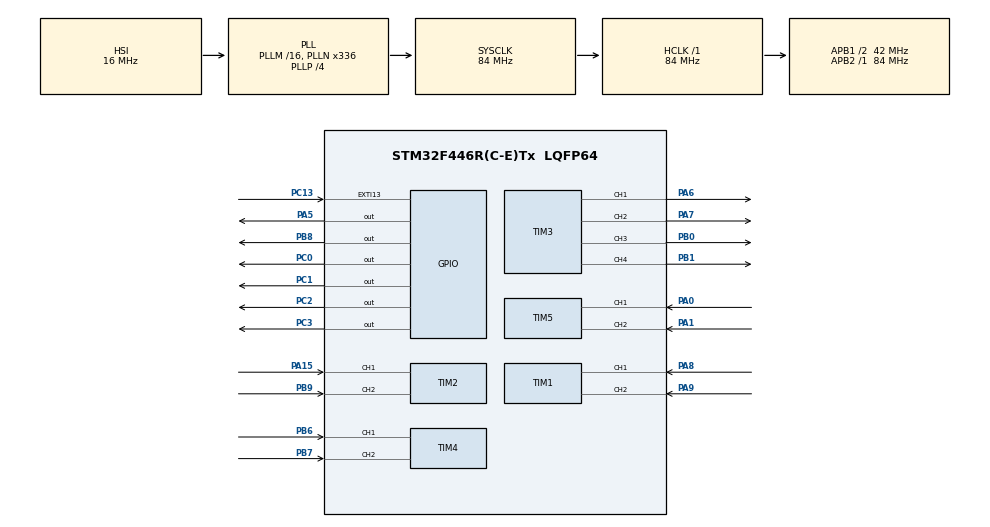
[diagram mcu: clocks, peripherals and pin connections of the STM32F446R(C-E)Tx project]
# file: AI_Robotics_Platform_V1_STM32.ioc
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Mcu.Family=STM32F4
Mcu.Name=STM32F446R(C-E)Tx
Mcu.Package=LQFP64
NUCLEO-F446RE.BUTTON=1
NUCLEO-F446RE.LD1=true
NVIC.EXTI15_10_IRQn=true\:0\:0\:false\:false\:true\:false\:true\:true
NVIC.PriorityGroup=NVIC_PRIORITYGROUP_0
NVIC.USART2_IRQn=true\:0\:0\:false\:false\:true\:true\:true\:true
PA0-WKUP.Signal=S_TIM5_CH1
PA1.Signal=S_TIM5_CH2
PA13.GPIO_Label=TMS
PA13.Signal=SYS_JTMS-SWDIO
PA14.GPIO_Label=TCK
PA14.Signal=SYS_JTCK-SWCLK
PA15.Signal=S_TIM2_CH1_ETR
PA2.GPIO_Label=USART_TX
PA2.Signal=USART2_TX
PA3.GPIO_Label=USART_RX
PA3.Signal=USART2_RX
PA5.Signal=GPIO_Output
PA6.Signal=S_TIM3_CH1
PA7.Signal=S_TIM3_CH2
PA8.Signal=S_TIM1_CH1
PA9.Signal=S_TIM1_CH2
PB0.Signal=S_TIM3_CH3
PB1.Signal=S_TIM3_CH4
PB3.GPIO_Label=SWO
PB3.Signal=SYS_JTDO-SWO
PB6.Signal=S_TIM4_CH1
PB7.Signal=S_TIM4_CH2
PB8.Signal=GPIO_Output
PB9.Signal=S_TIM2_CH2
PC0.Signal=GPIO_Output
PC1.Signal=GPIO_Output
PC13.Signal=GPXTI13
PC14-OSC32_IN.Signal=RCC_OSC32_IN
PC15-OSC32_OUT.Signal=RCC_OSC32_OUT
PC2.Signal=GPIO_Output
PC3.Signal=GPIO_Output
PH0-OSC_IN.Signal=RCC_OSC_IN
PH1-OSC_OUT.Signal=RCC_OSC_OUT
ProjectManager.HeapSize=0x200
ProjectManager.StackSize=0x400
ProjectManager.TargetToolchain=STM32CubeIDE
USART2.BaudRate=115200
USART2.VirtualMode=VM_ASYNC
RCC.AHBFreq_Value=84000000
RCC.APB1CLKDivider=RCC_HCLK_DIV2
RCC.APB1Freq_Value=42000000
RCC.APB1TimFreq_Value=84000000
RCC.APB2Freq_Value=84000000
RCC.APB2TimFreq_Value=84000000
RCC.CortexFreq_Value=84000000
RCC.FLatency-AdvancedSettings=FLASH_LATENCY_2
RCC.HCLKFreq_Value=84000000
RCC.HSE_VALUE=8000000
RCC.HSI_VALUE=16000000
RCC.LSE_VALUE=32768
RCC.PLLN=336
RCC.PLLP=RCC_PLLP_DIV4
RCC.SYSCLKFreq_VALUE=84000000
RCC.SYSCLKSource=RCC_SYSCLKSOURCE_PLLCLK
RCC.USBFreq_Value=168000000
RCC.VCOOutputFreq_Value=336000000
SH.S_TIM1_CH1.0=TIM1_CH1,Encoder_Interface
SH.S_TIM1_CH2.0=TIM1_CH2,Encoder_Interface
SH.S_TIM2_CH1_ETR.0=TIM2_CH1,Encoder_Interface
SH.S_TIM2_CH2.0=TIM2_CH2,Encoder_Interface
SH.S_TIM3_CH1.0=TIM3_CH1,PWM Generation1 CH1
SH.S_TIM3_CH2.0=TIM3_CH2,PWM Generation2 CH2
SH.S_TIM3_CH3.0=TIM3_CH3,PWM Generation3 CH3
SH.S_TIM3_CH4.0=TIM3_CH4,PWM Generation4 CH4
SH.S_TIM4_CH1.0=TIM4_CH1,Encoder_Interface
SH.S_TIM4_CH2.0=TIM4_CH2,Encoder_Interface
SH.S_TIM5_CH1.0=TIM5_CH1,Encoder_Interface
SH.S_TIM5_CH2.0=TIM5_CH2,Encoder_Interface
TIM3.Channel-PWM\ Generation1\ CH1=TIM_CHANNEL_1
TIM3.Channel-PWM\ Generation2\ CH2=TIM_CHANNEL_2
TIM3.Channel-PWM\ Generation3\ CH3=TIM_CHANNEL_3
TIM3.Channel-PWM\ Generation4\ CH4=TIM_CHANNEL_4
VP_NUCLEO-F446RE_VS_BSP_COMMON.Mode=COMMON
VP_TIM3_VS_ClockSourceINT.Mode=Internal
board=NUCLEO-F446RE

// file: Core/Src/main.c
/* USER CODE BEGIN Header */
/**
  ******************************************************************************
  * @file           : main.c
  * @brief          : Main program body
  ******************************************************************************
  * @attention
  *
  * Copyright (c) 2026 STMicroelectronics.
  * All rights reserved.
  *
  * This software is licensed under terms that can be found in the LICENSE file
  * in the root directory of this software component.
  * If no LICENSE file comes with this software, it is provided AS-IS.
  *
  ******************************************************************************
  */
/* USER CODE END Header */
#include "main.h"

/* USER CODE BEGIN Includes */

#include "communication/communication.h"
#include "control/control.h"
#include "motor/motor.h"
#include "sensor/sensor.h"

/* USER CODE END Includes */

TIM_HandleTypeDef htim1;
TIM_HandleTypeDef htim2;
TIM_HandleTypeDef htim3;
TIM_HandleTypeDef htim4;
TIM_HandleTypeDef htim5;
UART_HandleTypeDef huart2;

void SystemClock_Config(void);
static void MX_GPIO_Init(void);
static void MX_TIM1_Init(void);
static void MX_TIM2_Init(void);
static void MX_TIM3_Init(void);
static void MX_TIM4_Init(void);
static void MX_TIM5_Init(void);
static void MX_USART2_UART_Init(void);

int main(void)
{

  /* MCU Configuration--------------------------------------------------------*/

  /* Reset of all peripherals, Initializes the Flash interface and the Systick. */
  HAL_Init();

  /* Configure the system clock */
  SystemClock_Config();

  /* Initialize all configured peripherals */
  MX_GPIO_Init();
  MX_TIM1_Init();
  MX_TIM2_Init();
  MX_TIM3_Init();
  MX_TIM4_Init();
  MX_TIM5_Init();
  MX_USART2_UART_Init();
  /* USER CODE BEGIN 2 */

  Motor_Init();
  Sensor_Init();
  Control_Init();
  Communication_Init();

  /* USER CODE END 2 */

  /* Initialize leds */
  BSP_LED_Init(LED2);

  /* Initialize USER push-button, will be used to trigger an interrupt each time it's pressed.*/
  BSP_PB_Init(BUTTON_USER, BUTTON_MODE_EXTI);

  /* Infinite loop */
  while (1)
  {

    /* USER CODE BEGIN 3 */
    Communication_Update();
    Sensor_Update();
    Control_Update();
  }
  /* USER CODE END 3 */
}

void SystemClock_Config(void)
{
  RCC_OscInitTypeDef RCC_OscInitStruct = {0};
  RCC_ClkInitTypeDef RCC_ClkInitStruct = {0};

  /** Configure the main internal regulator output voltage
  */
  __HAL_RCC_PWR_CLK_ENABLE();
  __HAL_PWR_VOLTAGESCALING_CONFIG(PWR_REGULATOR_VOLTAGE_SCALE3);

  /** Initializes the RCC Oscillators according to the specified parameters
  * in the RCC_OscInitTypeDef structure.
  */
  RCC_OscInitStruct.OscillatorType = RCC_OSCILLATORTYPE_HSI;
  RCC_OscInitStruct.HSIState = RCC_HSI_ON;
  RCC_OscInitStruct.HSICalibrationValue = RCC_HSICALIBRATION_DEFAULT;
  RCC_OscInitStruct.PLL.PLLState = RCC_PLL_ON;
  RCC_OscInitStruct.PLL.PLLSource = RCC_PLLSOURCE_HSI;
  RCC_OscInitStruct.PLL.PLLM = 16;
  RCC_OscInitStruct.PLL.PLLN = 336;
  RCC_OscInitStruct.PLL.PLLP = RCC_PLLP_DIV4;
  RCC_OscInitStruct.PLL.PLLQ = 2;
  RCC_OscInitStruct.PLL.PLLR = 2;
  if (HAL_RCC_OscConfig(&RCC_OscInitStruct) != HAL_OK)
  {
    Error_Handler();
  }

  /** Initializes the CPU, AHB and APB buses clocks
  */
  RCC_ClkInitStruct.ClockType = RCC_CLOCKTYPE_HCLK|RCC_CLOCKTYPE_SYSCLK
                              |RCC_CLOCKTYPE_PCLK1|RCC_CLOCKTYPE_PCLK2;
  RCC_ClkInitStruct.SYSCLKSource = RCC_SYSCLKSOURCE_PLLCLK;
  RCC_ClkInitStruct.AHBCLKDivider = RCC_SYSCLK_DIV1;
  RCC_ClkInitStruct.APB1CLKDivider = RCC_HCLK_DIV2;
  RCC_ClkInitStruct.APB2CLKDivider = RCC_HCLK_DIV1;

  if (HAL_RCC_ClockConfig(&RCC_ClkInitStruct, FLASH_LATENCY_2) != HAL_OK)
  {
    Error_Handler();
  }
}

static void MX_TIM1_Init(void)
{

  TIM_Encoder_InitTypeDef sConfig = {0};
  TIM_MasterConfigTypeDef sMasterConfig = {0};

  htim1.Instance = TIM1;
  htim1.Init.Prescaler = 0;
  htim1.Init.CounterMode = TIM_COUNTERMODE_UP;
  htim1.Init.Period = 65535;
  htim1.Init.ClockDivision = TIM_CLOCKDIVISION_DIV1;
  htim1.Init.RepetitionCounter = 0;
  htim1.Init.AutoReloadPreload = TIM_AUTORELOAD_PRELOAD_DISABLE;
  sConfig.EncoderMode = TIM_ENCODERMODE_TI1;
  sConfig.IC1Polarity = TIM_ICPOLARITY_RISING;
  sConfig.IC1Selection = TIM_ICSELECTION_DIRECTTI;
  sConfig.IC1Prescaler = TIM_ICPSC_DIV1;
  sConfig.IC1Filter = 0;
  sConfig.IC2Polarity = TIM_ICPOLARITY_RISING;
  sConfig.IC2Selection = TIM_ICSELECTION_DIRECTTI;
  sConfig.IC2Prescaler = TIM_ICPSC_DIV1;
  sConfig.IC2Filter = 0;
  if (HAL_TIM_Encoder_Init(&htim1, &sConfig) != HAL_OK)
  {
    Error_Handler();
  }
  sMasterConfig.MasterOutputTrigger = TIM_TRGO_RESET;
  sMasterConfig.MasterSlaveMode = TIM_MASTERSLAVEMODE_DISABLE;
  if (HAL_TIMEx_MasterConfigSynchronization(&htim1, &sMasterConfig) != HAL_OK)
  {
    Error_Handler();
  }

}

static void MX_TIM2_Init(void)
{

  TIM_Encoder_InitTypeDef sConfig = {0};
  TIM_MasterConfigTypeDef sMasterConfig = {0};

  htim2.Instance = TIM2;
  htim2.Init.Prescaler = 0;
  htim2.Init.CounterMode = TIM_COUNTERMODE_UP;
  htim2.Init.Period = 4294967295;
  htim2.Init.ClockDivision = TIM_CLOCKDIVISION_DIV1;
  htim2.Init.AutoReloadPreload = TIM_AUTORELOAD_PRELOAD_DISABLE;
  sConfig.EncoderMode = TIM_ENCODERMODE_TI1;
  sConfig.IC1Polarity = TIM_ICPOLARITY_RISING;
  sConfig.IC1Selection = TIM_ICSELECTION_DIRECTTI;
  sConfig.IC1Prescaler = TIM_ICPSC_DIV1;
  sConfig.IC1Filter = 0;
  sConfig.IC2Polarity = TIM_ICPOLARITY_RISING;
  sConfig.IC2Selection = TIM_ICSELECTION_DIRECTTI;
  sConfig.IC2Prescaler = TIM_ICPSC_DIV1;
  sConfig.IC2Filter = 0;
  if (HAL_TIM_Encoder_Init(&htim2, &sConfig) != HAL_OK)
  {
    Error_Handler();
  }
  sMasterConfig.MasterOutputTrigger = TIM_TRGO_RESET;
  sMasterConfig.MasterSlaveMode = TIM_MASTERSLAVEMODE_DISABLE;
  if (HAL_TIMEx_MasterConfigSynchronization(&htim2, &sMasterConfig) != HAL_OK)
  {
    Error_Handler();
  }

}

static void MX_TIM3_Init(void)
{

  TIM_ClockConfigTypeDef sClockSourceConfig = {0};
  TIM_MasterConfigTypeDef sMasterConfig = {0};
  TIM_OC_InitTypeDef sConfigOC = {0};

  htim3.Instance = TIM3;
  htim3.Init.Prescaler = 0;
  htim3.Init.CounterMode = TIM_COUNTERMODE_UP;
  htim3.Init.Period = 65535;
  htim3.Init.ClockDivision = TIM_CLOCKDIVISION_DIV1;
  htim3.Init.AutoReloadPreload = TIM_AUTORELOAD_PRELOAD_DISABLE;
  if (HAL_TIM_Base_Init(&htim3) != HAL_OK)
  {
    Error_Handler();
  }
  sClockSourceConfig.ClockSource = TIM_CLOCKSOURCE_INTERNAL;
  if (HAL_TIM_ConfigClockSource(&htim3, &sClockSourceConfig) != HAL_OK)
  {
    Error_Handler();
  }
  if (HAL_TIM_PWM_Init(&htim3) != HAL_OK)
  {
    Error_Handler();
  }
  sMasterConfig.MasterOutputTrigger = TIM_TRGO_RESET;
  sMasterConfig.MasterSlaveMode = TIM_MASTERSLAVEMODE_DISABLE;
  if (HAL_TIMEx_MasterConfigSynchronization(&htim3, &sMasterConfig) != HAL_OK)
  {
    Error_Handler();
  }
  sConfigOC.OCMode = TIM_OCMODE_PWM1;
  sConfigOC.Pulse = 0;
  sConfigOC.OCPolarity = TIM_OCPOLARITY_HIGH;
  sConfigOC.OCFastMode = TIM_OCFAST_DISABLE;
  if (HAL_TIM_PWM_ConfigChannel(&htim3, &sConfigOC, TIM_CHANNEL_1) != HAL_OK)
  {
    Error_Handler();
  }
  if (HAL_TIM_PWM_ConfigChannel(&htim3, &sConfigOC, TIM_CHANNEL_2) != HAL_OK)
  {
    Error_Handler();
  }
  if (HAL_TIM_PWM_ConfigChannel(&htim3, &sConfigOC, TIM_CHANNEL_3) != HAL_OK)
  {
    Error_Handler();
  }
  if (HAL_TIM_PWM_ConfigChannel(&htim3, &sConfigOC, TIM_CHANNEL_4) != HAL_OK)
  {
    Error_Handler();
  }
  HAL_TIM_MspPostInit(&htim3);

}

static void MX_TIM4_Init(void)
{

  TIM_Encoder_InitTypeDef sConfig = {0};
  TIM_MasterConfigTypeDef sMasterConfig = {0};

  htim4.Instance = TIM4;
  htim4.Init.Prescaler = 0;
  htim4.Init.CounterMode = TIM_COUNTERMODE_UP;
  htim4.Init.Period = 65535;
  htim4.Init.ClockDivision = TIM_CLOCKDIVISION_DIV1;
  htim4.Init.AutoReloadPreload = TIM_AUTORELOAD_PRELOAD_DISABLE;
  sConfig.EncoderMode = TIM_ENCODERMODE_TI1;
  sConfig.IC1Polarity = TIM_ICPOLARITY_RISING;
  sConfig.IC1Selection = TIM_ICSELECTION_DIRECTTI;
  sConfig.IC1Prescaler = TIM_ICPSC_DIV1;
  sConfig.IC1Filter = 0;
  sConfig.IC2Polarity = TIM_ICPOLARITY_RISING;
  sConfig.IC2Selection = TIM_ICSELECTION_DIRECTTI;
  sConfig.IC2Prescaler = TIM_ICPSC_DIV1;
  sConfig.IC2Filter = 0;
  if (HAL_TIM_Encoder_Init(&htim4, &sConfig) != HAL_OK)
  {
    Error_Handler();
  }
  sMasterConfig.MasterOutputTrigger = TIM_TRGO_RESET;
  sMasterConfig.MasterSlaveMode = TIM_MASTERSLAVEMODE_DISABLE;
  if (HAL_TIMEx_MasterConfigSynchronization(&htim4, &sMasterConfig) != HAL_OK)
  {
    Error_Handler();
  }

}

static void MX_TIM5_Init(void)
{

  TIM_Encoder_InitTypeDef sConfig = {0};
  TIM_MasterConfigTypeDef sMasterConfig = {0};

  htim5.Instance = TIM5;
  htim5.Init.Prescaler = 0;
  htim5.Init.CounterMode = TIM_COUNTERMODE_UP;
  htim5.Init.Period = 4294967295;
  htim5.Init.ClockDivision = TIM_CLOCKDIVISION_DIV1;
  htim5.Init.AutoReloadPreload = TIM_AUTORELOAD_PRELOAD_DISABLE;
  sConfig.EncoderMode = TIM_ENCODERMODE_TI1;
  sConfig.IC1Polarity = TIM_ICPOLARITY_RISING;
  sConfig.IC1Selection = TIM_ICSELECTION_DIRECTTI;
  sConfig.IC1Prescaler = TIM_ICPSC_DIV1;
  sConfig.IC1Filter = 0;
  sConfig.IC2Polarity = TIM_ICPOLARITY_RISING;
  sConfig.IC2Selection = TIM_ICSELECTION_DIRECTTI;
  sConfig.IC2Prescaler = TIM_ICPSC_DIV1;
  sConfig.IC2Filter = 0;
  if (HAL_TIM_Encoder_Init(&htim5, &sConfig) != HAL_OK)
  {
    Error_Handler();
  }
  sMasterConfig.MasterOutputTrigger = TIM_TRGO_RESET;
  sMasterConfig.MasterSlaveMode = TIM_MASTERSLAVEMODE_DISABLE;
  if (HAL_TIMEx_MasterConfigSynchronization(&htim5, &sMasterConfig) != HAL_OK)
  {
    Error_Handler();
  }

}

static void MX_USART2_UART_Init(void)
{
  huart2.Instance = USART2;
  huart2.Init.BaudRate = 115200;
  huart2.Init.WordLength = UART_WORDLENGTH_8B;
  huart2.Init.StopBits = UART_STOPBITS_1;
  huart2.Init.Parity = UART_PARITY_NONE;
  huart2.Init.Mode = UART_MODE_TX_RX;
  huart2.Init.HwFlowCtl = UART_HWCONTROL_NONE;
  huart2.Init.OverSampling = UART_OVERSAMPLING_16;
  if (HAL_UART_Init(&huart2) != HAL_OK)
  {
    Error_Handler();
  }
}

static void MX_GPIO_Init(void)
{
  GPIO_InitTypeDef GPIO_InitStruct = {0};

  /* GPIO Ports Clock Enable */
  __HAL_RCC_GPIOC_CLK_ENABLE();
  __HAL_RCC_GPIOH_CLK_ENABLE();
  __HAL_RCC_GPIOA_CLK_ENABLE();
  __HAL_RCC_GPIOB_CLK_ENABLE();

  /*Configure GPIO pin Output Level */
  HAL_GPIO_WritePin(GPIOC, GPIO_PIN_0|GPIO_PIN_1|GPIO_PIN_2|GPIO_PIN_3, GPIO_PIN_RESET);

  /*Configure GPIO pin Output Level */
  HAL_GPIO_WritePin(GPIOB, GPIO_PIN_8, GPIO_PIN_RESET);

  /*Configure GPIO pins : PC0 PC1 PC2 PC3 */
  GPIO_InitStruct.Pin = GPIO_PIN_0|GPIO_PIN_1|GPIO_PIN_2|GPIO_PIN_3;
  GPIO_InitStruct.Mode = GPIO_MODE_OUTPUT_PP;
  GPIO_InitStruct.Pull = GPIO_NOPULL;
  GPIO_InitStruct.Speed = GPIO_SPEED_FREQ_LOW;
  HAL_GPIO_Init(GPIOC, &GPIO_InitStruct);

  /*Configure GPIO pins : USART_TX_Pin USART_RX_Pin */
  GPIO_InitStruct.Pin = USART_TX_Pin|USART_RX_Pin;
  GPIO_InitStruct.Mode = GPIO_MODE_AF_PP;
  GPIO_InitStruct.Pull = GPIO_NOPULL;
  GPIO_InitStruct.Speed = GPIO_SPEED_FREQ_VERY_HIGH;
  GPIO_InitStruct.Alternate = GPIO_AF7_USART2;
  HAL_GPIO_Init(GPIOA, &GPIO_InitStruct);

  /*Configure GPIO pin : PB8 */
  GPIO_InitStruct.Pin = GPIO_PIN_8;
  GPIO_InitStruct.Mode = GPIO_MODE_OUTPUT_PP;
  GPIO_InitStruct.Pull = GPIO_NOPULL;
  GPIO_InitStruct.Speed = GPIO_SPEED_FREQ_LOW;
  HAL_GPIO_Init(GPIOB, &GPIO_InitStruct);

}

void Error_Handler(void)
{
  __disable_irq();
  while (1)
  {
  }
}
